# iostr731 register map
Registers are 16-bit, access not given, no defined reset value unless marked. A register's access mark holds for its fields unless they carry their own. Addresses are absolute; registers are grouped by the start of their names; [hi:lo] are bit positions; {n}, {i} and the like mark numbered series.

## BSPI2
0xFFFFE000 BSPI2_RXR
0xFFFFE004 BSPI2_TXR
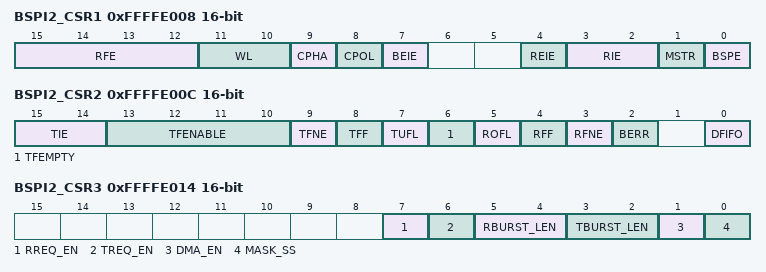
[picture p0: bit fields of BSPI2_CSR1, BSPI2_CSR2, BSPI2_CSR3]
0xFFFFE008 BSPI2_CSR1
  [15:12] RFE, [11:10] WL, [9] CPHA, [8] CPOL, [7] BEIE, [4] REIE, [3:2] RIE, [1] MSTR, [0] BSPE
0xFFFFE00C BSPI2_CSR2
  [15:14] TIE, [13:10] TFENABLE, [9] TFNE, [8] TFF, [7] TUFL, [6] TFEMPTY, [5] ROFL, [4] RFF, [3] RFNE, [2] BERR, [0] DFIFO
0xFFFFE010 BSPI2_CLK
  [7:0] DIV
0xFFFFE014 BSPI2_CSR3
  [7] RREQ_EN, [6] TREQ_EN, [5:4] RBURST_LEN, [3:2] TBURST_LEN, [1] DMA_EN, [0] MASK_SS

## TIM2
0xFFFFE400 TIM2_ICAR
0xFFFFE404 TIM2_ICBR
0xFFFFE408 TIM2_OCAR
0xFFFFE40C TIM2_OCBR
0xFFFFE410 TIM2_CNTR
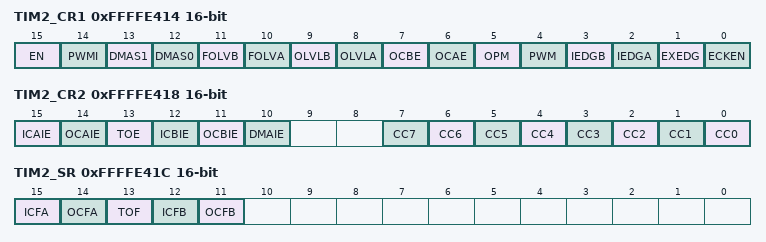
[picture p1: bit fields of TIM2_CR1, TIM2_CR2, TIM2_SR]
0xFFFFE414 TIM2_CR1
  [15] EN, [14] PWMI, [13] DMAS1, [12] DMAS0, [11] FOLVB, [10] FOLVA, [9] OLVLB, [8] OLVLA, [7] OCBE, [6] OCAE, [5] OPM, [4] PWM, [3] IEDGB, [2] IEDGA, [1] EXEDG, [0] ECKEN
0xFFFFE418 TIM2_CR2
  [15] ICAIE, [14] OCAIE, [13] TOE, [12] ICBIE, [11] OCBIE, [10] DMAIE, [n] CC{n} (n=0..7)
0xFFFFE41C TIM2_SR
  [15] ICFA, [14] OCFA, [13] TOF, [12] ICFB, [11] OCFB

## TIM3
0xFFFFE800 TIM3_ICAR
0xFFFFE804 TIM3_ICBR
0xFFFFE808 TIM3_OCAR
0xFFFFE80C TIM3_OCBR
0xFFFFE810 TIM3_CNTR
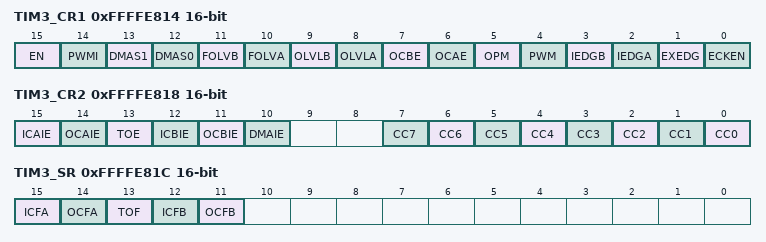
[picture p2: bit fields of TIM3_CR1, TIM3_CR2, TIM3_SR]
0xFFFFE814 TIM3_CR1
  [15] EN, [14] PWMI, [13] DMAS1, [12] DMAS0, [11] FOLVB, [10] FOLVA, [9] OLVLB, [8] OLVLA, [7] OCBE, [6] OCAE, [5] OPM, [4] PWM, [3] IEDGB, [2] IEDGA, [1] EXEDG, [0] ECKEN
0xFFFFE818 TIM3_CR2
  [15] ICAIE, [14] OCAIE, [13] TOE, [12] ICBIE, [11] OCBIE, [10] DMAIE, [n] CC{n} (n=0..7)
0xFFFFE81C TIM3_SR
  [15] ICFA, [14] OCFA, [13] TOF, [12] ICFB, [11] OCFB

## TIM4
0xFFFFEC00 TIM4_ICAR
0xFFFFEC04 TIM4_ICBR
0xFFFFEC08 TIM4_OCAR
0xFFFFEC0C TIM4_OCBR
0xFFFFEC10 TIM4_CNTR
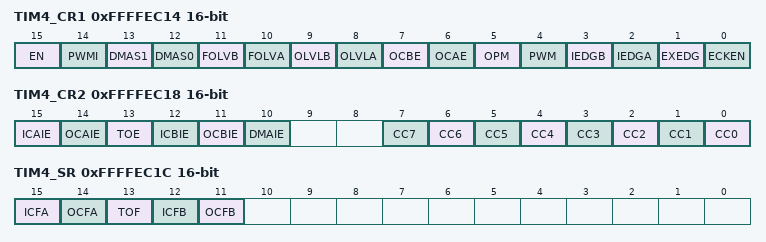
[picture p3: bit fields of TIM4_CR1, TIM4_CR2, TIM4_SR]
0xFFFFEC14 TIM4_CR1
  [15] EN, [14] PWMI, [13] DMAS1, [12] DMAS0, [11] FOLVB, [10] FOLVA, [9] OLVLB, [8] OLVLA, [7] OCBE, [6] OCAE, [5] OPM, [4] PWM, [3] IEDGB, [2] IEDGA, [1] EXEDG, [0] ECKEN
0xFFFFEC18 TIM4_CR2
  [15] ICAIE, [14] OCAIE, [13] TOE, [12] ICBIE, [11] OCBIE, [10] DMAIE, [n] CC{n} (n=0..7)
0xFFFFEC1C TIM4_SR
  [15] ICFA, [14] OCFA, [13] TOF, [12] ICFB, [11] OCFB

## DMA0
{0xFFFFF000+0x40*i} DMA0_SOURCEL{i} (i=0..3)
{0xFFFFF004+0x40*i} DMA0_SOURCEH{i} (i=0..3)
{0xFFFFF008+0x40*i} DMA0_DESTL{i} (i=0..3)
{0xFFFFF00C+0x40*i} DMA0_DESTH{i} (i=0..3)
{0xFFFFF010+0x40*i} DMA0_MAX{i} (i=0..3)
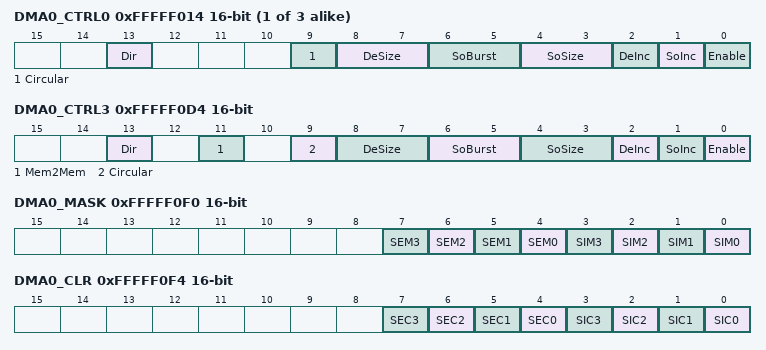
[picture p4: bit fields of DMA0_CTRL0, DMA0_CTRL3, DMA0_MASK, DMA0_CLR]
{0xFFFFF014+0x40*i} DMA0_CTRL{i} (i=0..2)
  [13] Dir, [9] Circular, [8:7] DeSize, [6:5] SoBurst, [4:3] SoSize, [2] DeInc, [1] SoInc, [0] Enable
{0xFFFFF018+0x40*i} DMA0_SOCURRH{i} (i=0..3)
{0xFFFFF01C+0x40*i} DMA0_SOCURRL{i} (i=0..3)
{0xFFFFF020+0x40*i} DMA0_DECURRH{i} (i=0..3)
{0xFFFFF024+0x40*i} DMA0_DECURRL{i} (i=0..3)
{0xFFFFF028+0x40*i} DMA0_TCNT{i} (i=0..3)
{0xFFFFF02C+0x40*i} DMA0_LUBuff{i} (i=0..3)
0xFFFFF0D4 DMA0_CTRL3
  [13] Dir, [11] Mem2Mem, [9] Circular, [8:7] DeSize, [6:5] SoBurst, [4:3] SoSize, [2] DeInc, [1] SoInc, [0] Enable
0xFFFFF0F0 DMA0_MASK
  [n+4] SEM{n} (n=0..3), [n] SIM{n} (n=0..3)
0xFFFFF0F4 DMA0_CLR
  [n+4] SEC{n} (n=0..3), [n] SIC{n} (n=0..3)
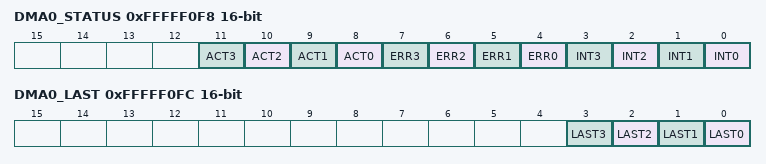
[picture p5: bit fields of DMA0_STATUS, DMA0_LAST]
0xFFFFF0F8 DMA0_STATUS
  [n+8] ACT{n} (n=0..3), [n+4] ERR{n} (n=0..3), [n] INT{n} (n=0..3)
0xFFFFF0FC DMA0_LAST
  [n] LAST{n} (n=0..3)

## DMA1
{0xFFFFF100+0x40*i} DMA1_SOURCEL{i} (i=0..3)
{0xFFFFF104+0x40*i} DMA1_SOURCEH{i} (i=0..3)
{0xFFFFF108+0x40*i} DMA1_DESTL{i} (i=0..3)
{0xFFFFF10C+0x40*i} DMA1_DESTH{i} (i=0..3)
{0xFFFFF110+0x40*i} DMA1_MAX{i} (i=0..3)
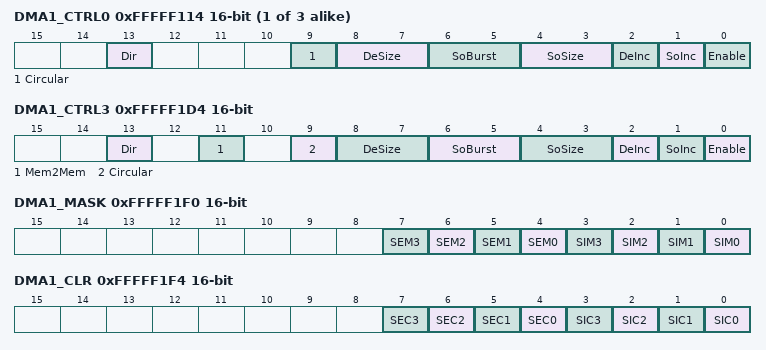
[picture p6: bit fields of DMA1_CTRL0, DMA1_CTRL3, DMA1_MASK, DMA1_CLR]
{0xFFFFF114+0x40*i} DMA1_CTRL{i} (i=0..2)
  [13] Dir, [9] Circular, [8:7] DeSize, [6:5] SoBurst, [4:3] SoSize, [2] DeInc, [1] SoInc, [0] Enable
{0xFFFFF118+0x40*i} DMA1_SOCURRH{i} (i=0..3)
{0xFFFFF11C+0x40*i} DMA1_SOCURRL{i} (i=0..3)
{0xFFFFF120+0x40*i} DMA1_DECURRH{i} (i=0..3)
{0xFFFFF124+0x40*i} DMA1_DECURRL{i} (i=0..3)
{0xFFFFF128+0x40*i} DMA1_TCNT{i} (i=0..3)
{0xFFFFF12C+0x40*i} DMA1_LUBuff{i} (i=0..3)
0xFFFFF1D4 DMA1_CTRL3
  [13] Dir, [11] Mem2Mem, [9] Circular, [8:7] DeSize, [6:5] SoBurst, [4:3] SoSize, [2] DeInc, [1] SoInc, [0] Enable
0xFFFFF1F0 DMA1_MASK
  [n+4] SEM{n} (n=0..3), [n] SIM{n} (n=0..3)
0xFFFFF1F4 DMA1_CLR
  [n+4] SEC{n} (n=0..3), [n] SIC{n} (n=0..3)
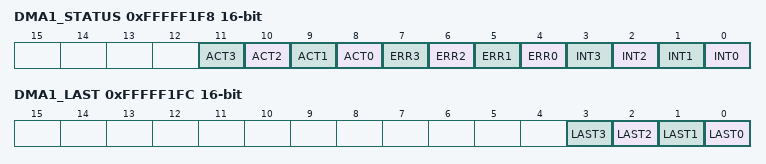
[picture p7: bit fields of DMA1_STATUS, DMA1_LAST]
0xFFFFF1F8 DMA1_STATUS
  [n+8] ACT{n} (n=0..3), [n+4] ERR{n} (n=0..3), [n] INT{n} (n=0..3)
0xFFFFF1FC DMA1_LAST
  [n] LAST{n} (n=0..3)
